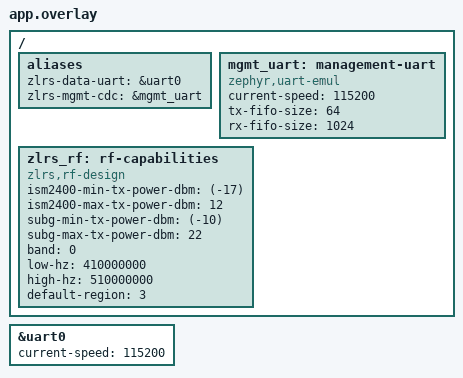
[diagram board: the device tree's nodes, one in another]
/ {
 aliases { zlrs-data-uart = &uart0; zlrs-mgmt-cdc = &mgmt_uart; };
 mgmt_uart: management-uart {
  compatible = "zephyr,uart-emul";
  current-speed = <115200>;
  tx-fifo-size = <64>;
  rx-fifo-size = <1024>;
 };
 zlrs_rf: rf-capabilities {
  compatible = "zlrs,rf-design";
  ism2400-min-tx-power-dbm = <(-17)>;
  ism2400-max-tx-power-dbm = <12>;
  subg-min-tx-power-dbm = <(-10)>;
  subg-max-tx-power-dbm = <22>;
  band = <0>;
  low-hz = <410000000>;
  high-hz = <510000000>;
  default-region = <3>;
 };
};
&uart0 { current-speed = <115200>; };
